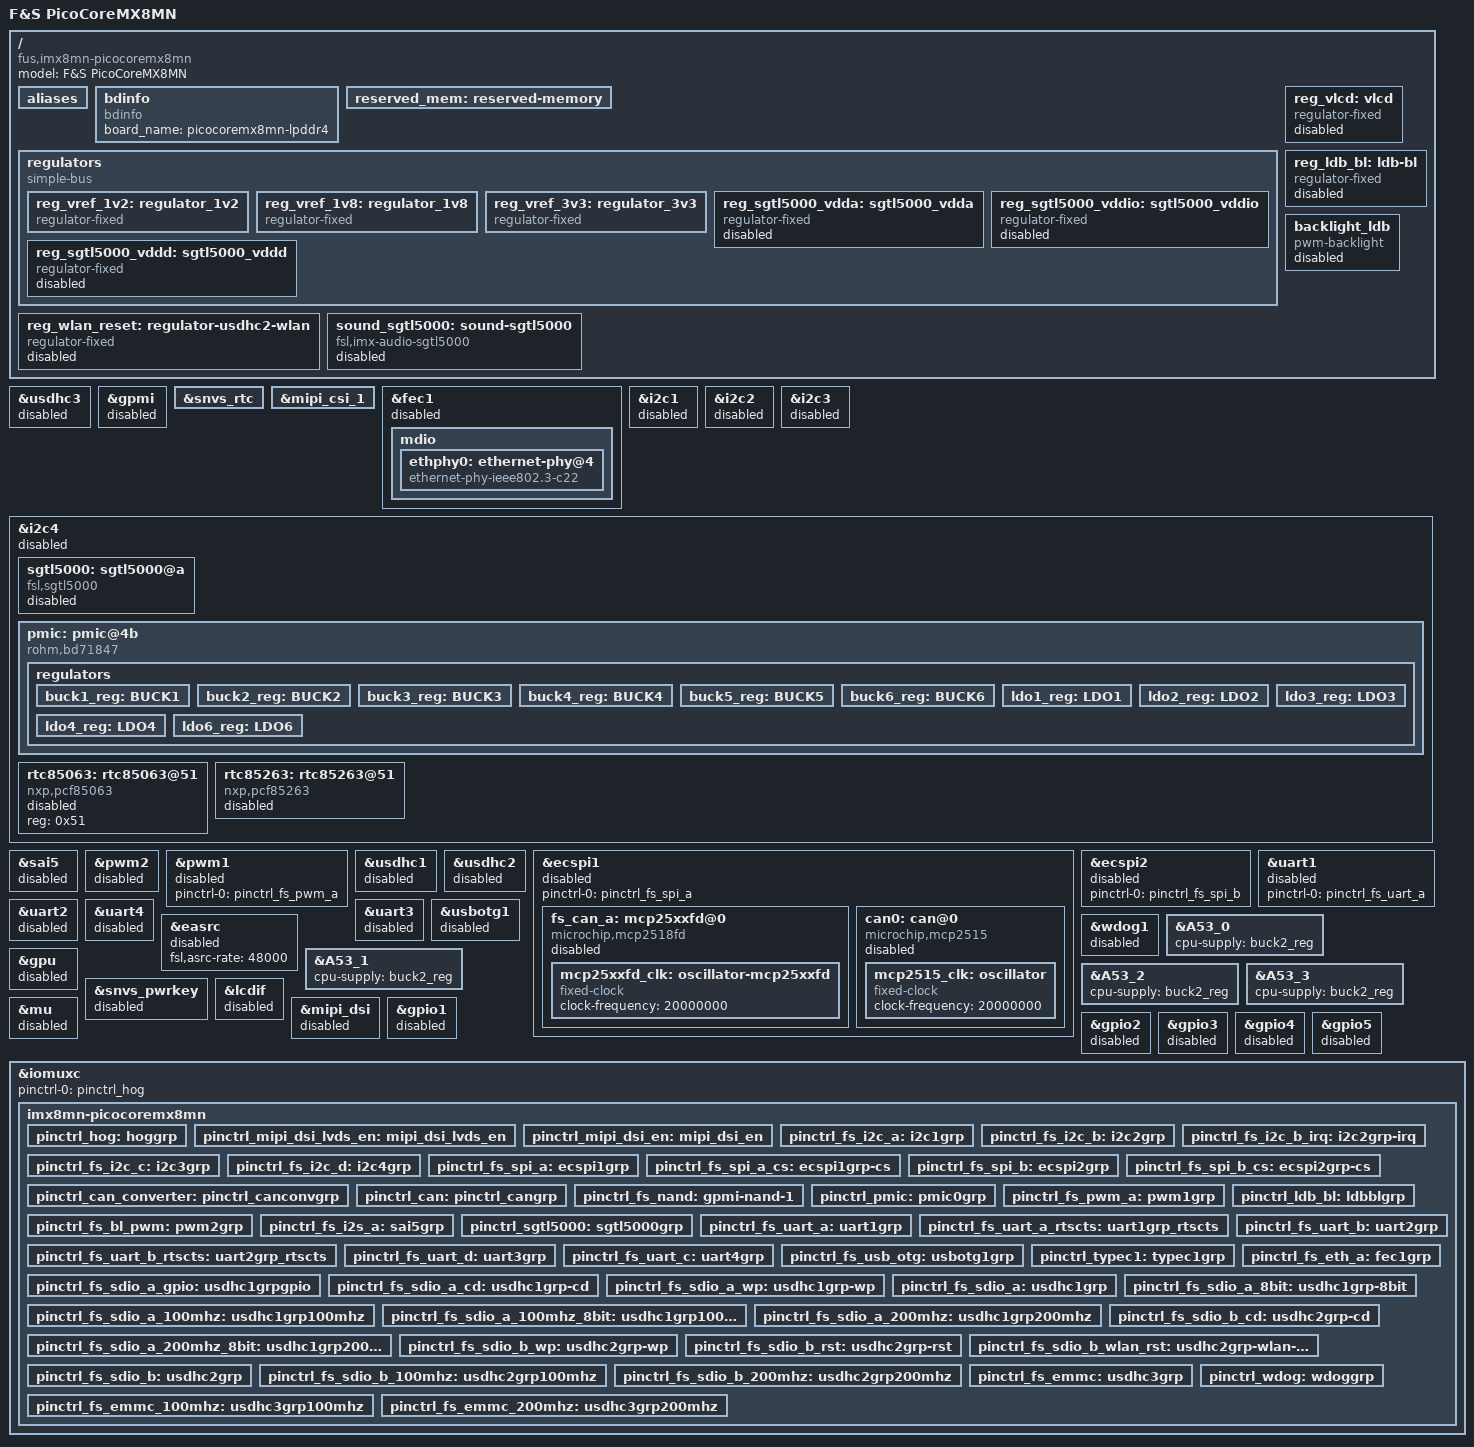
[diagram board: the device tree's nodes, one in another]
/*
 * Copyright (C) 2026 F&S Elektronik Systeme GmbH
 *
 * This program is free software; you can redistribute it and/or modify
 * it under the terms of the GNU General Public License version 2 as
 * published by the Free Software Foundation.
 */

#include <dt-bindings/pwm/pwm.h>
#include <dt-bindings/rtc/nxp,pcf85263.h>
#include <dt-bindings/usb/pd.h>

/* Internal nodes */
fs_emmc: &usdhc3 {};
fs_nand: &gpmi {};
fs_rtc_soc: &snvs_rtc {};

/* External nodes */
fs_csi: &mipi_csi_1 {};
fs_eth_a: &fec1 {};
fs_i2c_a: &i2c1 {};
fs_i2c_b: &i2c2 {};
fs_i2c_c: &i2c3 {};
fs_i2c_d: &i2c4 {};
fs_i2s_a: &sai5 {};
fs_bl_pwm: &pwm2 {};
fs_pwm_a: &pwm1 {};
fs_sdio_a: &usdhc1 {};
fs_sdio_b: &usdhc2 {};
fs_spi_a: &ecspi1 {};
fs_spi_b: &ecspi2 {};
fs_uart_a: &uart1 {};
fs_uart_b: &uart2 {};
fs_uart_c: &uart4 {};
fs_uart_d: &uart3 {};
fs_usb_otg: &usbotg1 {};

/ {
	model = "F&S PicoCoreMX8MN";
	compatible = "fus,imx8mn-picocoremx8mn", "fsl,imx8mn";

	aliases {
		nand = &gpmi;
		emmc = &usdhc3;
		rtcpcf85063 = &rtc85063;
		rtcpcf85263 = &rtc85263;
		sound-sgtl5000 = &sound_sgtl5000;
		sgtl5000 = &sgtl5000;
	};

	bdinfo: bdinfo {
		compatible = "bdinfo";
		board_name = "picocoremx8mn-lpddr4";
	};

	reserved_mem: reserved-memory {
		#address-cells = <2>;
		#size-cells = <2>;
		ranges;
	};

	regulators {
		compatible = "simple-bus";
		#address-cells = <1>;
		#size-cells = <0>;

		reg_vref_1v2: regulator_1v2 {
			compatible = "regulator-fixed";
			regulator-name = "vref-1V2";
			regulator-min-microvolt = <1200000>;
			regulator-max-microvolt = <1200000>;
			regulator-always-on;
		};

		reg_vref_1v8: regulator_1v8 {
			compatible = "regulator-fixed";
			regulator-name = "vref-1V8";
			regulator-min-microvolt = <1800000>;
			regulator-max-microvolt = <1800000>;
			regulator-always-on;
		};

		reg_vref_3v3: regulator_3v3 {
			compatible = "regulator-fixed";
			regulator-name = "vref-3V3";
			regulator-min-microvolt = <3300000>;
			regulator-max-microvolt = <3300000>;
			regulator-always-on;
		};

		/* SGTL5000 analog voltage */
		/omit-if-no-ref/
		reg_sgtl5000_vdda: sgtl5000_vdda {
			compatible = "regulator-fixed";
			regulator-name = "VDDA-supply";
			regulator-min-microvolt = <3300000>;
			regulator-max-microvolt = <3300000>;
			regulator-always-on;
			status = "disabled";
		};

		/* SGTL5000 I/O voltage */
		/omit-if-no-ref/
		reg_sgtl5000_vddio: sgtl5000_vddio {
			compatible = "regulator-fixed";
			regulator-name = "VDDIO-supply";
			regulator-min-microvolt = <3300000>;
			regulator-max-microvolt = <3300000>;
			regulator-always-on;
			status = "disabled";
		};

		/* SGTL5000 internal digital voltage */
		/omit-if-no-ref/
		reg_sgtl5000_vddd: sgtl5000_vddd {
			compatible = "regulator-fixed";
			regulator-name = "VDDD-supply";
			regulator-min-microvolt = <1500000>;
			regulator-max-microvolt = <1500000>;
			regulator-always-on;
			status = "disabled";
		};
	};

	/omit-if-no-ref/
	reg_wlan_reset: regulator-usdhc2-wlan {
		compatible = "regulator-fixed";
		regulator-name = "WLAN_RESET";
		regulator-min-microvolt = <3300000>;
		regulator-max-microvolt = <3300000>;
		gpio = <&gpio5 0 GPIO_ACTIVE_LOW>;
		off-on-delay = <1000>;
		enable-active-high;
		status = "disabled";
	};

	/omit-if-no-ref/
	reg_vlcd: vlcd {
		compatible = "regulator-fixed";
		regulator-name = "VLCD";
		gpio = <&gpio4 28 GPIO_ACTIVE_HIGH>;
		regulator-min-microvolt = <3300000>;
		regulator-max-microvolt = <3300000>;
		enable-active-high;
		status = "disabled";
	};

	/omit-if-no-ref/
	reg_ldb_bl: ldb-bl {
		compatible = "regulator-fixed";
		regulator-name = "ldb-bl";
		pinctrl-names = "default";
		pinctrl-0 = <&pinctrl_ldb_bl>;
		gpio = <&gpio5 3 GPIO_ACTIVE_HIGH>;
		regulator-min-microvolt = <3300000>;
		regulator-max-microvolt = <3300000>;
		enable-active-high;
		status = "disabled";
	};

	sound_sgtl5000: sound-sgtl5000 {
		#sound-dai-cells = <0>;
		compatible = "fsl,imx-audio-sgtl5000";
		model = "imx-sgtl5000";
		audio-cpu = <&sai5>;
		audio-codec = <&sgtl5000>;
		audio-asrc = <&easrc>;
		audio-routing =
			"LINE_IN", "Line In Jack",
			"Mic Jack", "Mic Bias",
			"MIC_IN", "Mic Jack",
			"Line Out Jack", "LINE_OUT",
			"Headphone Jack", "HP_OUT";
		status = "disabled";
	};

	backlight_ldb: backlight_ldb {
		compatible = "pwm-backlight";
		#pwm-cells = <3>;
		pwms = <&pwm2 0 3000000 PWM_POLARITY_INVERTED>;
		power-supply = <&reg_ldb_bl>;
		brightness-levels = <0 1 5 10 18 28 41 56
				     73 92 113 137 163 192 222 255>;
		default-brightness-level = <14>;
		fb-names = "mxs-lcdif0";
		status = "disabled";
	};
};

&fs_i2c_a {
	clock-frequency = <100000>;
	pinctrl-names = "default";
	pinctrl-0 = <&pinctrl_fs_i2c_a>;
	status = "disabled";
};

&fs_i2c_b {
	clock-frequency = <100000>;
	pinctrl-names = "default";
	pinctrl-0 = <&pinctrl_fs_i2c_b>, <&pinctrl_fs_i2c_b_irq>;
	status = "disabled";

	/* NOTE: not ported from the old CONFIG_PICOCOREMX8MN_CAMERA_BASLER_daA4200
	 * board-revision-independent example - the daA4200 basler camera on I2C_B
	 * needs its own follow-up add-on dts before this can be re-enabled,
	 * mirrors how picocoremx8mm-common.dtsi handled the same TODO. */
};

&fs_i2c_c {
	clock-frequency = <100000>;
	pinctrl-names = "default";
	pinctrl-0 = <&pinctrl_fs_i2c_c>;
	status = "disabled";
};

&fs_i2c_d {
	clock-frequency = <100000>;
	pinctrl-names = "default";
	pinctrl-0 = <&pinctrl_fs_i2c_d>;
	status = "disabled";

	sgtl5000: sgtl5000@a {
		#sound-dai-cells = <0>;
		compatible = "fsl,sgtl5000";
		/* MCLK is needed for i2c sgtl driver */
		pinctrl-names = "default";
		pinctrl-0 = <&pinctrl_sgtl5000>;
		reg = <0xa>;
		mono2both;
		clocks = <&clk IMX8MN_CLK_SAI5_ROOT>;
		VDDA-supply = <&reg_sgtl5000_vdda>;
		VDDIO-supply = <&reg_sgtl5000_vddio>;
		VDDD-supply = <&reg_sgtl5000_vddd>;
		status = "disabled";
	};

	/* PMIC */
	pmic: pmic@4b {
		compatible = "rohm,bd71847";
		reg = <0x4b>;
		pinctrl-names = "default";
		pinctrl-0 = <&pinctrl_pmic>;
		interrupt-parent = <&gpio5>;
		interrupts = <2 GPIO_ACTIVE_LOW>;
		rohm,reset-snvs-powered;

		#clock-cells = <0>;
		clocks = <&osc_32k 0>;
		clock-output-names = "clk-32k-out";

		regulators {
			buck1_reg: BUCK1 {
				regulator-name = "BUCK1";
				regulator-min-microvolt = <700000>;
				regulator-max-microvolt = <1300000>;
				regulator-boot-on;
				regulator-always-on;
				regulator-ramp-delay = <1250>;
				rohm,dvs-run-voltage = <850000>;
				rohm,dvs-suspend-voltage = <750000>;
			};

			buck2_reg: BUCK2 {
				regulator-name = "BUCK2";
				regulator-min-microvolt = <700000>;
				regulator-max-microvolt = <1300000>;
				regulator-boot-on;
				regulator-always-on;
				regulator-ramp-delay = <1250>;
				rohm,dvs-run-voltage = <1000000>;
				rohm,dvs-idle-voltage = <900000>;
				rohm,dvs-suspend-voltage = <0>;
			};

			buck3_reg: BUCK3 {
				// BUCK5 in datasheet
				regulator-name = "BUCK3";
				regulator-min-microvolt = <700000>;
				regulator-max-microvolt = <1350000>;
				regulator-boot-on;
				regulator-always-on;
			};

			buck4_reg: BUCK4 {
				// BUCK6 in datasheet
				regulator-name = "BUCK4";
				regulator-min-microvolt = <3000000>;
				regulator-max-microvolt = <3300000>;
				regulator-boot-on;
				regulator-always-on;
			};

			buck5_reg: BUCK5 {
				// BUCK7 in datasheet
				regulator-name = "BUCK5";
				regulator-min-microvolt = <1605000>;
				regulator-max-microvolt = <1995000>;
				regulator-boot-on;
				regulator-always-on;
			};

			buck6_reg: BUCK6 {
				// BUCK8 in datasheet
				regulator-name = "BUCK6";
				regulator-min-microvolt = <800000>;
				regulator-max-microvolt = <1400000>;
				regulator-boot-on;
				regulator-always-on;
			};

			ldo1_reg: LDO1 {
				regulator-name = "LDO1";
				regulator-min-microvolt = <1600000>;
				regulator-max-microvolt = <1900000>;
				regulator-boot-on;
				regulator-always-on;
			};

			ldo2_reg: LDO2 {
				regulator-name = "LDO2";
				regulator-min-microvolt = <800000>;
				regulator-max-microvolt = <900000>;
				regulator-boot-on;
				regulator-always-on;
			};

			ldo3_reg: LDO3 {
				regulator-name = "LDO3";
				regulator-min-microvolt = <1800000>;
				regulator-max-microvolt = <3300000>;
				regulator-boot-on;
				regulator-always-on;
			};

			ldo4_reg: LDO4 {
				regulator-name = "LDO4";
				regulator-min-microvolt = <900000>;
				regulator-max-microvolt = <1800000>;
				regulator-boot-on;
				regulator-always-on;
			};

			ldo6_reg: LDO6 {
				regulator-name = "LDO6";
				regulator-min-microvolt = <900000>;
				regulator-max-microvolt = <1800000>;
				regulator-boot-on;
				regulator-always-on;
			};
		};
	};

	/* rtc85063 and rtc85263 are alternative RTC chip options at the same
	 * address - only one is ever populated. Uncertain which one is the
	 * current default population, verify against the schematic.
	 */
	rtc85063: rtc85063@51 {
		compatible = "nxp,pcf85063";
		reg = <0x51>;
		status = "disabled";
	};

	rtc85263: rtc85263@51 {
		compatible = "nxp,pcf85263";
		reg = <0x51>;
		clock-out = <PCF85263_CLK_OUT_32p768kHz>;

		quartz-load-capacitance = <PCF85263_QUARTZCAP_12p5pF>;
		quartz-drive-strength = <PCF85263_QUARTZDRIVE_LOW>;
		status = "disabled";
	};
};

&fs_pwm_a {
	pinctrl-names = "default";
	pinctrl-0 = <&pinctrl_fs_pwm_a>;
	status = "disabled";
};

&fs_bl_pwm {
	pinctrl-names = "default";
	pinctrl-0 = <&pinctrl_fs_bl_pwm>;
	#pwm-cells = <3>;
	keep-power;
	status = "disabled";
};

&fs_i2s_a {
	#sound-dai-cells = <0>;
	pinctrl-names = "default";
	pinctrl-0 = <&pinctrl_fs_i2s_a>;
	assigned-clocks = <&clk IMX8MN_CLK_SAI5>;
	assigned-clock-parents = <&clk IMX8MN_AUDIO_PLL1_OUT>;
	assigned-clock-rates = <24576000>;
	status = "disabled";
};

&easrc {
	fsl,asrc-rate = <48000>;
	status = "disabled";
};

&fs_spi_a {
	#address-cells = <1>;
	#size-cells = <0>;
	pinctrl-names = "default";
	pinctrl-0 = <&pinctrl_fs_spi_a>;
	status = "disabled";

	/* alternative populated option A: on-module CAN-FD controller */
	fs_can_a: mcp25xxfd@0 {
		compatible = "microchip,mcp2518fd";
		reg = <0>;
		pinctrl-names = "default";
		pinctrl-0 = <&pinctrl_can>;
		spi-max-frequency = <10000000>;
		interrupts-extended = <&gpio4 26 IRQ_TYPE_LEVEL_LOW>;
		clocks = <&mcp25xxfd_clk>;
		status = "disabled";

		mcp25xxfd_clk: oscillator-mcp25xxfd {
			#clock-cells = <0>;
			compatible = "fixed-clock";
			clock-frequency = <20000000>; //20MHz
		};
	};

	/* alternative populated option B: SPI-to-CAN converter add-on module,
	 * mutually exclusive with fs_can_a above - only one is ever enabled */
	can0: can@0 {
		compatible = "microchip,mcp2515";
		reg = <0>;
		pinctrl-names = "default";
		pinctrl-0 = <&pinctrl_can_converter>;
		clocks = <&mcp2515_clk>;
		interrupt-parent = <&gpio1>;
		interrupts = <9 IRQ_TYPE_EDGE_FALLING>;
		spi-max-frequency = <10000000>;
		status = "disabled";

		mcp2515_clk: oscillator {
			#clock-cells = <0>;
			compatible = "fixed-clock";
			clock-frequency = <20000000>; //20MHz
		};
	};
};

&fs_spi_b {
	#address-cells = <1>;
	#size-cells = <0>;
	pinctrl-names = "default";
	pinctrl-0 = <&pinctrl_fs_spi_b>;
	status = "disabled";
};

&fs_eth_a {
	pinctrl-names = "default";
	pinctrl-0 = <&pinctrl_fs_eth_a>;
	phy-mode = "rgmii-id";
	phy-handle = <&ethphy0>;
	fsl,magic-packet;
	status = "disabled";

	mdio {
		#address-cells = <1>;
		#size-cells = <0>;

		ethphy0: ethernet-phy@4 {
			compatible = "ethernet-phy-ieee802.3-c22";
			reg = <4>;
			interrupt-parent = <&gpio1>;
			interrupts = <4 0>;
			at803x,led-act-blind-workaround;
			at803x,eee-okay;
			at803x,vddio-1p8v;
		};
	};
};

&fs_uart_a { /* console */
	pinctrl-names = "default";
	pinctrl-0 = <&pinctrl_fs_uart_a>;
	status = "disabled";
};

&fs_uart_b {
	pinctrl-names = "default";
	pinctrl-0 = <&pinctrl_fs_uart_b>;
	assigned-clocks = <&clk IMX8MN_CLK_UART2>;
	assigned-clock-parents = <&clk IMX8MN_SYS_PLL1_80M>;
	status = "disabled";
};

&fs_uart_c {
	pinctrl-names = "default";
	pinctrl-0 = <&pinctrl_fs_uart_c>;
	assigned-clocks = <&clk IMX8MN_CLK_UART4>;
	assigned-clock-parents = <&clk IMX8MN_SYS_PLL1_80M>;
	status = "disabled";
};

&fs_uart_d {
	pinctrl-names = "default";
	pinctrl-0 = <&pinctrl_fs_uart_d>;
	assigned-clocks = <&clk IMX8MN_CLK_UART3>;
	assigned-clock-parents = <&clk IMX8MN_SYS_PLL1_80M>;
	status = "disabled";
};

&fs_usb_otg {
	pinctrl-names = "default";
	pinctrl-0 = <&pinctrl_fs_usb_otg>;
	disable-over-current;
	picophy,pre-emp-curr-control = <3>;
	picophy,dc-vol-level-adjust = <7>;
	status = "disabled";
};

&fs_sdio_a {
	assigned-clocks = <&clk IMX8MN_CLK_USDHC1>;
	assigned-clock-rates = <200000000>;
	pinctrl-names = "default", "state_100mhz", "state_200mhz";
	pinctrl-0 = <&pinctrl_fs_sdio_a>, <&pinctrl_fs_sdio_a_gpio>;
	pinctrl-1 = <&pinctrl_fs_sdio_a_100mhz>, <&pinctrl_fs_sdio_a_gpio>;
	pinctrl-2 = <&pinctrl_fs_sdio_a_200mhz>, <&pinctrl_fs_sdio_a_gpio>;
	bus-width = <4>;
	vmmc-supply = <&reg_vref_3v3>;
	vqmmc-supply = <&reg_vref_3v3>;
	pm-ignore-notify;
	keep-power-in-suspend;
	status = "disabled";
};

/* WLAN and SD_B are mutually exclusive alternatives on this controller -
 * board dts enables exactly one of them. */
&fs_sdio_b {
	pinctrl-names = "default", "state_100mhz", "state_200mhz";
	pinctrl-0 = <&pinctrl_fs_sdio_b>, <&pinctrl_fs_sdio_b_rst>;
	pinctrl-1 = <&pinctrl_fs_sdio_b_100mhz>, <&pinctrl_fs_sdio_b_rst>;
	pinctrl-2 = <&pinctrl_fs_sdio_b_200mhz>, <&pinctrl_fs_sdio_b_rst>;
	bus-width = <4>;
	vmmc-supply = <&reg_vref_3v3>;
	vqmmc-supply = <&reg_vref_3v3>;
	keep-power-in-suspend;
	status = "disabled";
};

/* NAND and eMMC are alternative boot media; original dts enabled both
 * unconditionally and let U-Boot fix up whichever chip is absent at
 * runtime - kept as two independently switchable nodes here instead,
 * board dts enables the one(s) actually populated. */
&fs_emmc {
	assigned-clocks = <&clk IMX8MN_CLK_USDHC3>;
	assigned-clock-rates = <400000000>;
	pinctrl-names = "default", "state_100mhz", "state_200mhz";
	pinctrl-0 = <&pinctrl_fs_emmc>;
	pinctrl-1 = <&pinctrl_fs_emmc_100mhz>;
	pinctrl-2 = <&pinctrl_fs_emmc_200mhz>;
	bus-width = <8>;
	non-removable;
	status = "disabled";
};

&fs_nand {
	pinctrl-names = "default";
	pinctrl-0 = <&pinctrl_fs_nand>;
	fsl,use-minimum-ecc;
	status = "disabled";
};

&wdog1 {
	pinctrl-names = "default";
	pinctrl-0 = <&pinctrl_wdog>;
	fsl,ext-reset-output;
	status = "disabled";
};

&A53_0 {
	cpu-supply = <&buck2_reg>;
};

&A53_1 {
	cpu-supply = <&buck2_reg>;
};

&A53_2 {
	cpu-supply = <&buck2_reg>;
};

&A53_3 {
	cpu-supply = <&buck2_reg>;
};

&gpu {
	status = "disabled";
};

&snvs_pwrkey {
	status = "disabled";
};

&lcdif {
	status = "disabled";
};

&mipi_dsi {
	status = "disabled";
};

/* CM4/remoteproc was never implemented for this board (old file only had a
 * dead #if 0 rpmsg-audio TODO) - mu is gated the same way as the mx8mm
 * sibling for consistency, but no imx8mm-cm4-style node exists to enable
 * alongside it. */
&mu {
	status = "disabled";
};

/* GPIO declarations */
&gpio1 {
	gpio-line-names =
	/* 0 */   "ETH_SW_PME", "GPIO_J1_7", "PMIC_WDOG", "SD_A_VSEL",
	/* 4 */   "LVDS_STBY", "ETH_SW_RST", "SD_A_CD", "SD_A_WP",
	/* 8 */   "LVDS_RST", "SE050_ENA", "PMIC_IRQ_B", "ETH_SW_INT",
	/* 12 */  "USB_OTG_PWR", "GPIO_J1_2", "USB_HOST_PWR", "LVDS_CLK",
	/* 16 */  "ETH_A_D1P", "ETH_A_D1N", "ETH_A_D4N", "ETH_A_D4P",
	/* 20 */  "ETH_A_D3N", "ETH_A_D3P", "ETH_A_D2N", "ETH_A_D2P",
	/* 24 */  "ETH_B_D1P", "ETH_B_D1N", "ETH_B_D2P", "ETH_B_D2N",
	/* 28 */  "ETH_B_D3P", "ETH_B_D3N", "", "";
	status = "disabled";
};

&gpio2 {
	gpio-line-names =
	/* 0 */   "SD_A_CLK", "SD_A_CMD", "SD_A_DATA0", "SD_A_DATA1",
	/* 4 */   "SD_A_DATA2", "SD_A_DATA3", "SD_A_DATA4", "SD_A_DATA5",
	/* 8 */   "SD_A_DATA6", "SD_A_DATA7", "SD_A_RST", "",
	/* 12 */  "SD_B_CD", "SD_B_CLK", "SD_B_CMD", "SD_B_DATA0",
	/* 16 */  "SD_B_DATA1", "SD_B_DATA2", "SD_B_DATA3", "SD_B_RST",
	/* 20 */  "SD_B_WP", "", "", "",
	/* 24 */  "", "", "", "",
	/* 28 */  "", "", "", "";
	status = "disabled";
};

&gpio3 {
	gpio-line-names =
	/* 0 */   "QSPI_SCLK", "QSPI_CS0", "SD_C_STROBE", "SD_C_DATA5",
	/* 4 */   "SD_C_DATA6", "SD_C_DATA7", "QSPI_DATA0", "QSPI_DATA1",
	/* 8 */   "QSPI_DATA2", "QSPI_DATA3", "SD_C_DATA0", "SD_C_DATA1",
	/* 12 */  "SD_C_DATA2", "SD_C_DATA3", "", "SD_C_DATA4",
	/* 16 */  "SD_C_RESET_B", "SD_C_CLK", "SD_C_CMD", "mPCIE_PERST",
	/* 20 */  "mPCIE_WAKE", "I2S_DIN", "I2S_LRCLK", "I2S_SCLK",
	/* 24 */  "I2S_DOUT", "I2S_MCLK", "", "",
	/* 28 */  "", "", "", "";
	status = "disabled";
};

&gpio4 {
	gpio-line-names =
	/* 0 */   "", "", "", "",
	/* 4 */   "", "", "", "",
	/* 8 */   "", "", "", "",
	/* 12 */  "", "", "", "",
	/* 16 */  "", "", "", "",
	/* 20 */  "", "UART_A_TXD", "UART_A_RXD", "UART_A_CTS",
	/* 24 */  "UART_A_RTS", "CAN_INT0", "CAN_INT1", "CAN_CLKO/SOF",
	/* 28 */  "CAN_INT", "UART_B_RTS", "UART_B_CTS", "UART_B_RXD";
	status = "disabled";
};

&gpio5 {
	gpio-line-names =
	/* 0 */   "UART_B_TXD", "VLCD_ON", "I2C_B_IRQ", "BL_ON",
	/* 4 */   "BL_PWM", "PWM", "SPI_A_SCLK", "SPI_A_MOSI",
	/* 8 */   "SPI_A_MISO", "SPI_A_SS0", "SPI_C_SCLK", "SPI_C_MOSI",
	/* 12 */  "SPI_C_MISO", "SPI_C_SS0", "I2C_D_SCL", "I2C_D_SDA",
	/* 16 */  "I2C_B_SCL", "I2C_B_SDA", "I2C_C_SCL", "I2C_C_SDA",
	/* 20 */  "I2C_A_SCL", "I2C_A_SDA", "SPI_B_SCLK", "SPI_B_MOSI",
	/* 24 */  "SPI_B_MISO", "SPI_B_SS0", "UART_D_RXD", "UART_D_TXD",
	/* 28 */  "UART_C_RXD", "UART_C_TXD", "", "";
	status = "disabled";
};

&iomuxc {
	pinctrl-names = "default";
	pinctrl-0 = <&pinctrl_hog>;

	imx8mn-picocoremx8mn {
		/* Pin configs that don't belong anywhere else */
		pinctrl_hog: hoggrp {
			fsl,pins = <
				MX8MN_IOMUXC_GPIO1_IO08_GPIO1_IO8	0x00104
				MX8MN_IOMUXC_GPIO1_IO10_GPIO1_IO10	0x00104
				MX8MN_IOMUXC_GPIO1_IO11_GPIO1_IO11	0x00104
				MX8MN_IOMUXC_GPIO1_IO13_GPIO1_IO13	0x00104
				MX8MN_IOMUXC_GPIO1_IO14_GPIO1_IO14	0x00104
				MX8MN_IOMUXC_SAI2_MCLK_GPIO4_IO27	0x00104
				MX8MN_IOMUXC_SAI5_RXFS_GPIO3_IO19	0x00104
				MX8MN_IOMUXC_SAI5_RXC_GPIO3_IO20	0x00104
				/* VLCD ON */
				MX8MN_IOMUXC_SAI3_RXFS_GPIO4_IO28	0x00104
				/* SEC CHIP */
				MX8MN_IOMUXC_SAI3_TXD_GPIO5_IO1		0x00104
			>;
		};

		pinctrl_mipi_dsi_lvds_en: mipi_dsi_lvds_en {
			fsl,pins = <
				/* LVDS RESET / TC358764 RST */
				MX8MN_IOMUXC_SAI3_TXFS_GPIO4_IO31	0x00016
				/* For EXTCLK use the following setting
				 * in your display DTS
				 */
//				 MX8MN_IOMUXC_GPIO1_IO15_CCMSRCGPCMIX_CLKO2	0x00059
				MX8MN_IOMUXC_GPIO1_IO15_GPIO1_IO15	0x00016
			>;
		};

		pinctrl_mipi_dsi_en: mipi_dsi_en {
			fsl,pins = <
				/* MIPI_RSTn */
				MX8MN_IOMUXC_GPIO1_IO01_GPIO1_IO1	0x00104
			>;
		};

		pinctrl_fs_i2c_a: i2c1grp {
			fsl,pins = <
				MX8MN_IOMUXC_I2C1_SCL_I2C1_SCL		0x400001c3
				MX8MN_IOMUXC_I2C1_SDA_I2C1_SDA		0x400001c3
			>;
		};

		pinctrl_fs_i2c_b: i2c2grp {
			fsl,pins = <
				MX8MN_IOMUXC_I2C2_SCL_I2C2_SCL		0x400001c3
				MX8MN_IOMUXC_I2C2_SDA_I2C2_SDA		0x400001c3
			>;
		};

		/* I2C_B_IRQn -> Touch often needs hysteresis */
		pinctrl_fs_i2c_b_irq: i2c2grp-irq {
			fsl,pins = <
				MX8MN_IOMUXC_GPIO1_IO00_GPIO1_IO0	0x00144
			>;
		};

		pinctrl_fs_i2c_c: i2c3grp {
			fsl,pins = <
				MX8MN_IOMUXC_I2C3_SCL_I2C3_SCL		0x400001c3
				MX8MN_IOMUXC_I2C3_SDA_I2C3_SDA		0x400001c3
			>;
		};

		pinctrl_fs_i2c_d: i2c4grp {
			fsl,pins = <
				MX8MN_IOMUXC_I2C4_SCL_I2C4_SCL		0x400001c3
				MX8MN_IOMUXC_I2C4_SDA_I2C4_SDA		0x400001c3
			>;
		};

		pinctrl_fs_spi_a: ecspi1grp {
			fsl,pins = <
				MX8MN_IOMUXC_ECSPI1_SCLK_ECSPI1_SCLK	0x00082
				MX8MN_IOMUXC_ECSPI1_MOSI_ECSPI1_MOSI	0x00082
				MX8MN_IOMUXC_ECSPI1_MISO_ECSPI1_MISO	0x00082
			>;
		};

		pinctrl_fs_spi_a_cs: ecspi1grp-cs {
			fsl,pins = <
				MX8MN_IOMUXC_ECSPI1_SS0_GPIO5_IO9	0x40000
			>;
		};

		pinctrl_fs_spi_b: ecspi2grp {
			fsl,pins = <
				MX8MN_IOMUXC_ECSPI2_SCLK_ECSPI2_SCLK	0x00082
				MX8MN_IOMUXC_ECSPI2_MOSI_ECSPI2_MOSI	0x00082
				MX8MN_IOMUXC_ECSPI2_MISO_ECSPI2_MISO	0x00082
			>;
		};

		pinctrl_fs_spi_b_cs: ecspi2grp-cs {
			fsl,pins = <
				MX8MN_IOMUXC_ECSPI2_SS0_GPIO5_IO13	0x40000
			>;
		};

		pinctrl_can_converter: pinctrl_canconvgrp {
			fsl,pins = <
				MX8MN_IOMUXC_GPIO1_IO09_GPIO1_IO9	0x00144
			>;
		};

		pinctrl_can: pinctrl_cangrp {
			fsl,pins = <
				/* CAN_CLKO/SOF */
				MX8MN_IOMUXC_SAI2_TXC_GPIO4_IO25	0x00104
				/* CAN_INTn */
				MX8MN_IOMUXC_SAI2_TXD0_GPIO4_IO26	0x00019
				/* CAN_INT0n */
				MX8MN_IOMUXC_SAI2_RXFS_GPIO4_IO21	0x00104
				/* CAN_INT1n */
				MX8MN_IOMUXC_SAI2_RXC_GPIO4_IO22	0x00104
			>;
		};

		pinctrl_fs_nand: gpmi-nand-1 {
			fsl,pins = <
				MX8MN_IOMUXC_NAND_ALE_RAWNAND_ALE	0x00096
				MX8MN_IOMUXC_NAND_CE0_B_RAWNAND_CE0_B	0x00096
				MX8MN_IOMUXC_NAND_CLE_RAWNAND_CLE	0x00096
				MX8MN_IOMUXC_NAND_DATA00_RAWNAND_DATA00	0x00096
				MX8MN_IOMUXC_NAND_DATA01_RAWNAND_DATA01	0x00096
				MX8MN_IOMUXC_NAND_DATA02_RAWNAND_DATA02	0x00096
				MX8MN_IOMUXC_NAND_DATA03_RAWNAND_DATA03	0x00096
				MX8MN_IOMUXC_NAND_DATA04_RAWNAND_DATA04	0x00096
				MX8MN_IOMUXC_NAND_DATA05_RAWNAND_DATA05	0x00096
				MX8MN_IOMUXC_NAND_DATA06_RAWNAND_DATA06	0x00096
				MX8MN_IOMUXC_NAND_DATA07_RAWNAND_DATA07	0x00096
				MX8MN_IOMUXC_NAND_RE_B_RAWNAND_RE_B	0x00096
				MX8MN_IOMUXC_NAND_READY_B_RAWNAND_READY_B	0x00056
				MX8MN_IOMUXC_NAND_WE_B_RAWNAND_WE_B	0x00096
				MX8MN_IOMUXC_NAND_WP_B_RAWNAND_WP_B	0x00096
			>;
		};

		pinctrl_pmic: pmic0grp {
			fsl,pins = <
				/* IRQn */
				MX8MN_IOMUXC_SAI3_MCLK_GPIO5_IO2	0x00041
			>;
		};

		pinctrl_fs_pwm_a: pwm1grp {
			fsl,pins = <
				MX8MN_IOMUXC_SPDIF_EXT_CLK_PWM1_OUT	0x00104
			>;
		};

		pinctrl_fs_bl_pwm: pwm2grp {
			fsl,pins = <
				MX8MN_IOMUXC_SPDIF_RX_PWM2_OUT		0x00104
			>;
		};

		pinctrl_ldb_bl: ldbblgrp {
			fsl,pins = <
				MX8MN_IOMUXC_SPDIF_TX_GPIO5_IO3		0x00104
			>;
		};

		pinctrl_fs_i2s_a: sai5grp {
			fsl,pins = <
				MX8MN_IOMUXC_SAI5_RXD1_SAI5_TX_SYNC	0x000d6
				MX8MN_IOMUXC_SAI5_RXD2_SAI5_TX_BCLK	0x000d6
				MX8MN_IOMUXC_SAI5_RXD3_SAI5_TX_DATA0	0x000d6
				MX8MN_IOMUXC_SAI5_RXD0_SAI5_RX_DATA0	0x000d6
			>;
		};

		pinctrl_sgtl5000: sgtl5000grp {
			fsl,pins = <
				MX8MN_IOMUXC_SAI5_MCLK_SAI5_MCLK	0x000d6
			>;
		};

		pinctrl_fs_uart_a: uart1grp {
			fsl,pins = <
				MX8MN_IOMUXC_UART1_RXD_UART1_DCE_RX	0x00140
				MX8MN_IOMUXC_UART1_TXD_UART1_DCE_TX	0x00140
			>;
		};

		pinctrl_fs_uart_a_rtscts: uart1grp_rtscts {
			fsl,pins = <
				/* CTS */
				MX8MN_IOMUXC_SAI2_RXD0_UART1_DCE_RTS_B	0x00140
				/* RTS */
				MX8MN_IOMUXC_SAI2_TXFS_UART1_DCE_CTS_B	0x00140
			>;
		};

		pinctrl_fs_uart_b: uart2grp {
			fsl,pins = <
				MX8MN_IOMUXC_UART2_RXD_UART2_DCE_RX	0x00140
				MX8MN_IOMUXC_UART2_TXD_UART2_DCE_TX	0x00140
			>;
		};

		pinctrl_fs_uart_b_rtscts: uart2grp_rtscts {
			fsl,pins = <
				/* CTS */
				MX8MN_IOMUXC_SAI3_RXC_UART2_DCE_CTS_B	0x00140
				/* RTS */
				MX8MN_IOMUXC_SAI3_RXD_UART2_DCE_RTS_B	0x00140
			>;
		};

		pinctrl_fs_uart_d: uart3grp {
			fsl,pins = <
				MX8MN_IOMUXC_UART3_RXD_UART3_DCE_RX	0x00140
				MX8MN_IOMUXC_UART3_TXD_UART3_DCE_TX	0x00140
			>;
		};

		pinctrl_fs_uart_c: uart4grp {
			fsl,pins = <
				MX8MN_IOMUXC_UART4_RXD_UART4_DCE_RX	0x00140
				MX8MN_IOMUXC_UART4_TXD_UART4_DCE_TX	0x00140
			>;
		};

		pinctrl_fs_usb_otg: usbotg1grp {
			fsl,pins = <
				MX8MN_IOMUXC_GPIO1_IO12_USB1_OTG_PWR	0x00144
			>;
		};

		pinctrl_typec1: typec1grp {
			fsl,pins = <
				MX8MN_IOMUXC_SAI2_RXFS_GPIO4_IO21	0x001c6
			>;
		};

		pinctrl_fs_eth_a: fec1grp {
			fsl,pins = <
				MX8MN_IOMUXC_ENET_MDC_ENET1_MDC		0x00003
				MX8MN_IOMUXC_ENET_MDIO_ENET1_MDIO	0x00003
				MX8MN_IOMUXC_ENET_TD3_ENET1_RGMII_TD3	0x0001f
				MX8MN_IOMUXC_ENET_TD2_ENET1_RGMII_TD2	0x0001f
				MX8MN_IOMUXC_ENET_TD1_ENET1_RGMII_TD1	0x0001f
				MX8MN_IOMUXC_ENET_TD0_ENET1_RGMII_TD0	0x0001f
				MX8MN_IOMUXC_ENET_RD3_ENET1_RGMII_RD3	0x00091
				MX8MN_IOMUXC_ENET_RD2_ENET1_RGMII_RD2	0x00091
				MX8MN_IOMUXC_ENET_RD1_ENET1_RGMII_RD1	0x00091
				MX8MN_IOMUXC_ENET_RD0_ENET1_RGMII_RD0	0x00091
				MX8MN_IOMUXC_ENET_TXC_ENET1_RGMII_TXC	0x0001f
				MX8MN_IOMUXC_ENET_RXC_ENET1_RGMII_RXC	0x00091
				MX8MN_IOMUXC_ENET_RX_CTL_ENET1_RGMII_RX_CTL	0x00091
				MX8MN_IOMUXC_ENET_TX_CTL_ENET1_RGMII_TX_CTL	0x0001f
				/* reset */
				MX8MN_IOMUXC_GPIO1_IO05_GPIO1_IO5	0x00019
				/* INTn */
				MX8MN_IOMUXC_GPIO1_IO04_GPIO1_IO4	0x00019
			>;
		};

		pinctrl_fs_sdio_a_gpio: usdhc1grpgpio {
			fsl,pins = <
				/* VSEL, 3,3V = PD, 1.8 = PU */
				MX8MN_IOMUXC_GPIO1_IO03_USDHC1_VSELECT	0x001d0
				/* RESET, high active */
				MX8MN_IOMUXC_SD1_RESET_B_USDHC1_RESET_B	0x00041
				/* SD_A_STROBE */
				MX8MN_IOMUXC_SD1_STROBE_GPIO2_IO11	0x00104
			>;
		};

		pinctrl_fs_sdio_a_cd: usdhc1grp-cd {
			fsl,pins = <
				MX8MN_IOMUXC_GPIO1_IO06_GPIO1_IO6	0x001c4
			>;
		};

		pinctrl_fs_sdio_a_wp: usdhc1grp-wp {
			fsl,pins = <
				MX8MN_IOMUXC_GPIO1_IO07_GPIO1_IO7	0x001c4
			>;
		};

		pinctrl_fs_sdio_a: usdhc1grp {
			fsl,pins = <
				MX8MN_IOMUXC_SD1_CLK_USDHC1_CLK		0x00190
				MX8MN_IOMUXC_SD1_CMD_USDHC1_CMD		0x001d0
				MX8MN_IOMUXC_SD1_DATA0_USDHC1_DATA0	0x001d0
				MX8MN_IOMUXC_SD1_DATA1_USDHC1_DATA1	0x001d0
				MX8MN_IOMUXC_SD1_DATA2_USDHC1_DATA2	0x001d0
				MX8MN_IOMUXC_SD1_DATA3_USDHC1_DATA3	0x001d0
			>;
		};

		pinctrl_fs_sdio_a_8bit: usdhc1grp-8bit {
			fsl,pins = <
				MX8MN_IOMUXC_SD1_CLK_USDHC1_CLK		0x00190
				MX8MN_IOMUXC_SD1_CMD_USDHC1_CMD		0x001d0
				MX8MN_IOMUXC_SD1_DATA0_USDHC1_DATA0	0x001d0
				MX8MN_IOMUXC_SD1_DATA1_USDHC1_DATA1	0x001d0
				MX8MN_IOMUXC_SD1_DATA2_USDHC1_DATA2	0x001d0
				MX8MN_IOMUXC_SD1_DATA3_USDHC1_DATA3	0x001d0
				MX8MN_IOMUXC_SD1_DATA4_USDHC1_DATA4	0x001d0
				MX8MN_IOMUXC_SD1_DATA5_USDHC1_DATA5	0x001d0
				MX8MN_IOMUXC_SD1_DATA6_USDHC1_DATA6	0x001d0
				MX8MN_IOMUXC_SD1_DATA7_USDHC1_DATA7	0x001d0
			>;
		};

		pinctrl_fs_sdio_a_100mhz: usdhc1grp100mhz {
			fsl,pins = <
				MX8MN_IOMUXC_SD1_CLK_USDHC1_CLK		0x00194
				MX8MN_IOMUXC_SD1_CMD_USDHC1_CMD		0x001d4
				MX8MN_IOMUXC_SD1_DATA0_USDHC1_DATA0	0x001d4
				MX8MN_IOMUXC_SD1_DATA1_USDHC1_DATA1	0x001d4
				MX8MN_IOMUXC_SD1_DATA2_USDHC1_DATA2	0x001d4
				MX8MN_IOMUXC_SD1_DATA3_USDHC1_DATA3	0x001d4
			>;
		};

		pinctrl_fs_sdio_a_100mhz_8bit: usdhc1grp100mhz-8bit {
			fsl,pins = <
				MX8MN_IOMUXC_SD1_CLK_USDHC1_CLK		0x00194
				MX8MN_IOMUXC_SD1_CMD_USDHC1_CMD		0x001d4
				MX8MN_IOMUXC_SD1_DATA0_USDHC1_DATA0	0x001d4
				MX8MN_IOMUXC_SD1_DATA1_USDHC1_DATA1	0x001d4
				MX8MN_IOMUXC_SD1_DATA2_USDHC1_DATA2	0x001d4
				MX8MN_IOMUXC_SD1_DATA3_USDHC1_DATA3	0x001d4
				MX8MN_IOMUXC_SD1_DATA4_USDHC1_DATA4	0x001d4
				MX8MN_IOMUXC_SD1_DATA5_USDHC1_DATA5	0x001d4
				MX8MN_IOMUXC_SD1_DATA6_USDHC1_DATA6	0x001d4
				MX8MN_IOMUXC_SD1_DATA7_USDHC1_DATA7	0x001d4
			>;
		};

		pinctrl_fs_sdio_a_200mhz: usdhc1grp200mhz {
			fsl,pins = <
				MX8MN_IOMUXC_SD1_CLK_USDHC1_CLK		0x00196
				MX8MN_IOMUXC_SD1_CMD_USDHC1_CMD		0x001d6
				MX8MN_IOMUXC_SD1_DATA0_USDHC1_DATA0	0x001d6
				MX8MN_IOMUXC_SD1_DATA1_USDHC1_DATA1	0x001d6
				MX8MN_IOMUXC_SD1_DATA2_USDHC1_DATA2	0x001d6
				MX8MN_IOMUXC_SD1_DATA3_USDHC1_DATA3	0x001d6
			>;
		};

		pinctrl_fs_sdio_a_200mhz_8bit: usdhc1grp200mhz-8bit {
			fsl,pins = <
				MX8MN_IOMUXC_SD1_CLK_USDHC1_CLK		0x00196
				MX8MN_IOMUXC_SD1_CMD_USDHC1_CMD		0x001d6
				MX8MN_IOMUXC_SD1_DATA0_USDHC1_DATA0	0x001d6
				MX8MN_IOMUXC_SD1_DATA1_USDHC1_DATA1	0x001d6
				MX8MN_IOMUXC_SD1_DATA2_USDHC1_DATA2	0x001d6
				MX8MN_IOMUXC_SD1_DATA3_USDHC1_DATA3	0x001d6
				MX8MN_IOMUXC_SD1_DATA4_USDHC1_DATA4	0x001d6
				MX8MN_IOMUXC_SD1_DATA5_USDHC1_DATA5	0x001d6
				MX8MN_IOMUXC_SD1_DATA6_USDHC1_DATA6	0x001d6
				MX8MN_IOMUXC_SD1_DATA7_USDHC1_DATA7	0x001d6
			>;
		};

		pinctrl_fs_sdio_b_cd: usdhc2grp-cd {
			fsl,pins = <
				MX8MN_IOMUXC_SD2_CD_B_GPIO2_IO12	0x001c4
			>;
		};

		pinctrl_fs_sdio_b_wp: usdhc2grp-wp {
			fsl,pins = <
				MX8MN_IOMUXC_SD2_WP_GPIO2_IO20		0x001c4
			>;
		};

		pinctrl_fs_sdio_b_rst: usdhc2grp-rst {
			fsl,pins = <
				MX8MN_IOMUXC_SD2_RESET_B_USDHC2_RESET_B	0x00041
			>;
		};

		pinctrl_fs_sdio_b_wlan_rst: usdhc2grp-wlan-rst {
			fsl,pins = <
				MX8MN_IOMUXC_SAI3_TXC_GPIO5_IO0		0x00144
			>;
		};

		pinctrl_fs_sdio_b: usdhc2grp {
			fsl,pins = <
				MX8MN_IOMUXC_SD2_CLK_USDHC2_CLK		0x00190
				MX8MN_IOMUXC_SD2_CMD_USDHC2_CMD		0x001d0
				MX8MN_IOMUXC_SD2_DATA0_USDHC2_DATA0	0x001d0
				MX8MN_IOMUXC_SD2_DATA1_USDHC2_DATA1	0x001d0
				MX8MN_IOMUXC_SD2_DATA2_USDHC2_DATA2	0x001d0
				MX8MN_IOMUXC_SD2_DATA3_USDHC2_DATA3	0x001d0
			>;
		};

		pinctrl_fs_sdio_b_100mhz: usdhc2grp100mhz {
			fsl,pins = <
				MX8MN_IOMUXC_SD2_CLK_USDHC2_CLK		0x00194
				MX8MN_IOMUXC_SD2_CMD_USDHC2_CMD		0x001d4
				MX8MN_IOMUXC_SD2_DATA0_USDHC2_DATA0	0x001d4
				MX8MN_IOMUXC_SD2_DATA1_USDHC2_DATA1	0x001d4
				MX8MN_IOMUXC_SD2_DATA2_USDHC2_DATA2	0x001d4
				MX8MN_IOMUXC_SD2_DATA3_USDHC2_DATA3	0x001d4
			>;
		};

		pinctrl_fs_sdio_b_200mhz: usdhc2grp200mhz {
			fsl,pins = <
				MX8MN_IOMUXC_SD2_CLK_USDHC2_CLK		0x00196
				MX8MN_IOMUXC_SD2_CMD_USDHC2_CMD		0x001d6
				MX8MN_IOMUXC_SD2_DATA0_USDHC2_DATA0	0x001d6
				MX8MN_IOMUXC_SD2_DATA1_USDHC2_DATA1	0x001d6
				MX8MN_IOMUXC_SD2_DATA2_USDHC2_DATA2	0x001d6
				MX8MN_IOMUXC_SD2_DATA3_USDHC2_DATA3	0x001d6
			>;
		};

		pinctrl_fs_emmc: usdhc3grp {
			fsl,pins = <
				MX8MN_IOMUXC_NAND_WE_B_USDHC3_CLK	0x00190
				MX8MN_IOMUXC_NAND_WP_B_USDHC3_CMD	0x001d0
				MX8MN_IOMUXC_NAND_DATA04_USDHC3_DATA0	0x001d0
				MX8MN_IOMUXC_NAND_DATA05_USDHC3_DATA1	0x001d0
				MX8MN_IOMUXC_NAND_DATA06_USDHC3_DATA2	0x001d0
				MX8MN_IOMUXC_NAND_DATA07_USDHC3_DATA3	0x001d0
				MX8MN_IOMUXC_NAND_RE_B_USDHC3_DATA4	0x001d0
				MX8MN_IOMUXC_NAND_CE2_B_USDHC3_DATA5	0x001d0
				MX8MN_IOMUXC_NAND_CE3_B_USDHC3_DATA6	0x001d0
				MX8MN_IOMUXC_NAND_CLE_USDHC3_DATA7	0x001d0
				MX8MN_IOMUXC_NAND_CE1_B_USDHC3_STROBE 	0x00190
				/* NAND READY -> RESET */
				MX8MN_IOMUXC_NAND_READY_B_USDHC3_RESET_B	0x00144
			>;
		};

		pinctrl_fs_emmc_100mhz: usdhc3grp100mhz {
			fsl,pins = <
				MX8MN_IOMUXC_NAND_WE_B_USDHC3_CLK	0x00194
				MX8MN_IOMUXC_NAND_WP_B_USDHC3_CMD	0x001d4
				MX8MN_IOMUXC_NAND_DATA04_USDHC3_DATA0	0x001d4
				MX8MN_IOMUXC_NAND_DATA05_USDHC3_DATA1	0x001d4
				MX8MN_IOMUXC_NAND_DATA06_USDHC3_DATA2	0x001d4
				MX8MN_IOMUXC_NAND_DATA07_USDHC3_DATA3	0x001d4
				MX8MN_IOMUXC_NAND_RE_B_USDHC3_DATA4	0x001d4
				MX8MN_IOMUXC_NAND_CE2_B_USDHC3_DATA5	0x001d4
				MX8MN_IOMUXC_NAND_CE3_B_USDHC3_DATA6	0x001d4
				MX8MN_IOMUXC_NAND_CLE_USDHC3_DATA7	0x001d4
				MX8MN_IOMUXC_NAND_CE1_B_USDHC3_STROBE 	0x00194
				/* NAND READY -> RESET */
				MX8MN_IOMUXC_NAND_READY_B_USDHC3_RESET_B	0x00144
			>;
		};

		pinctrl_fs_emmc_200mhz: usdhc3grp200mhz {
			fsl,pins = <
				MX8MN_IOMUXC_NAND_WE_B_USDHC3_CLK	0x00196
				MX8MN_IOMUXC_NAND_WP_B_USDHC3_CMD	0x001d6
				MX8MN_IOMUXC_NAND_DATA04_USDHC3_DATA0	0x001d6
				MX8MN_IOMUXC_NAND_DATA05_USDHC3_DATA1	0x001d6
				MX8MN_IOMUXC_NAND_DATA06_USDHC3_DATA2	0x001d6
				MX8MN_IOMUXC_NAND_DATA07_USDHC3_DATA3	0x001d6
				MX8MN_IOMUXC_NAND_RE_B_USDHC3_DATA4	0x001d6
				MX8MN_IOMUXC_NAND_CE2_B_USDHC3_DATA5	0x001d6
				MX8MN_IOMUXC_NAND_CE3_B_USDHC3_DATA6	0x001d6
				MX8MN_IOMUXC_NAND_CLE_USDHC3_DATA7	0x001d6
				MX8MN_IOMUXC_NAND_CE1_B_USDHC3_STROBE 	0x00196
				/* NAND READY -> RESET */
				MX8MN_IOMUXC_NAND_READY_B_USDHC3_RESET_B	0x00144
			>;
		};

		pinctrl_wdog: wdoggrp {
			fsl,pins = <
				MX8MN_IOMUXC_GPIO1_IO02_WDOG1_WDOG_B	0x000c6
			>;
		};
	};
};
